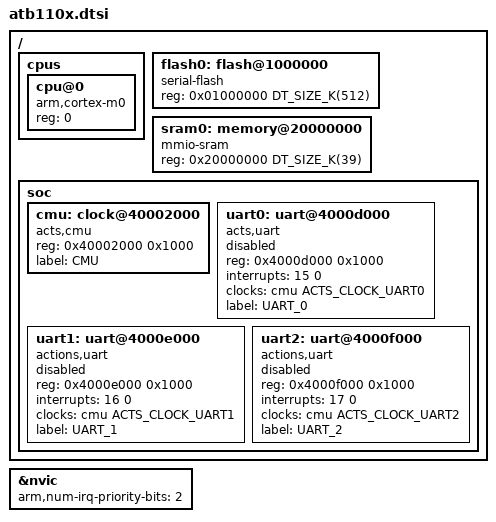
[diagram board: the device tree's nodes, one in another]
/*
 * Copyright (c) 2019 Actions (Zhuhai) Technology Co., Ltd
 * Copyright (c) 2019, Manivannan Sadhasivam <mani@kernel.org>
 *
 * SPDX-License-Identifier: Apache-2.0
 */

#include <arm/armv6-m.dtsi>
#include <mem.h>
#include <dt-bindings/clock/acts_cmu.h>

/ {
	cpus {
		#address-cells = <1>;
		#size-cells = <0>;

		cpu@0 {
			device_type = "cpu";
			compatible = "arm,cortex-m0";
			reg = <0>;
		};
	};

	flash0: flash@1000000 {
		compatible = "serial-flash";
		reg = <0x01000000 DT_SIZE_K(512)>;
	};

	sram0: memory@20000000 {
		device_type = "memory";
		compatible = "mmio-sram";
		reg = <0x20000000 DT_SIZE_K(39)>;
	};

	soc {
		cmu: clock@40002000 {
			compatible = "acts,cmu";
			reg = <0x40002000 0x1000>;
			#clock-cells = <1>;
			label = "CMU";
		};

		uart0: uart@4000d000 {
			compatible = "acts,uart";
			reg = <0x4000d000 0x1000>;
			interrupts = <15 0>;
			clocks = <&cmu ACTS_CLOCK_UART0>;
			label = "UART_0";
			status = "disabled";
		};

		uart1: uart@4000e000 {
			compatible = "actions,uart";
			reg = <0x4000e000 0x1000>;
			interrupts = <16 0>;
			clocks = <&cmu ACTS_CLOCK_UART1>;
			label = "UART_1";
			status = "disabled";
		};

		uart2: uart@4000f000 {
			compatible = "actions,uart";
			reg = <0x4000f000 0x1000>;
			interrupts = <17 0>;
			clocks = <&cmu ACTS_CLOCK_UART2>;
			label = "UART_2";
			status = "disabled";
		};
	};
};

&nvic {
	arm,num-irq-priority-bits = <2>;
};
